VERSION ""

NS_ :

BS_:

BU_:

BO_ 3221225472 VECTOR__INDEPENDENT_SIG_MSG: 0 Vector__XXX
 SG_ CID_Pos_Long_Dec : 44|20@1+ (1,0) [0|1000000] "" Vector__XXX
 SG_ CID_Pos_Long_Int : 40|4@1+ (1,120) [120|135] "" Vector__XXX
 SG_ CID_Pos_Lat_Dec : 20|20@1+ (1,0) [0|1000000] "" Vector__XXX
 SG_ Wave_Choose_ID_Long : 0|6@1+ (1,0) [0|63] "" Vector__XXX
 SG_ Wave_Mission_State_Long : 6|2@1+ (1,0) [0|3] "" Vector__XXX
 SG_ CID_Pos_Flag_SP_Long : 8|1@1+ (1,0) [0|1] "" Vector__XXX
 SG_ CID_Pos_Flag_GP_Long : 9|1@1+ (1,0) [0|1] "" Vector__XXX
 SG_ CID_Pos_Flag_IRR1_SP_Long : 10|1@1+ (1,0) [0|1] "" Vector__XXX
 SG_ CID_Pos_Flag_IRR1_GP_Long : 11|1@1+ (1,0) [0|1] "" Vector__XXX
 SG_ CID_Pos_Flag_IRR2_SP_Long : 12|1@1+ (1,0) [0|1] "" Vector__XXX
 SG_ CID_Pos_Flag_IRR2_GP_Long : 13|1@1+ (1,0) [0|1] "" Vector__XXX
 SG_ Wave_Send_Pos_complete_flag_Long : 14|1@1+ (1,0) [0|1] "" Vector__XXX
 SG_ CID_Pos_Long : 16|32@1- (1,0) [0|0] "" Vector__XXX
 SG_ Wave_Path_CID_CTC_Long : 55|1@1+ (1,0) [0|1] "" Vector__XXX
 SG_ CID_Pos_IR_Num_Long : 48|2@1+ (1,0) [0|2] "" Vector__XXX
 SG_ Wave_Choose_ID_Lat : 0|6@1+ (1,0) [0|63] "" Vector__XXX
 SG_ Wave_Mission_State_Lat : 6|2@1+ (1,0) [0|3] "" Vector__XXX
 SG_ CID_Pos_Flag_SP_Lat : 8|1@1+ (1,0) [0|1] "" Vector__XXX
 SG_ CID_Pos_Flag_GP_Lat : 9|1@1+ (1,0) [0|1] "" Vector__XXX
 SG_ CID_Pos_Flag_IRR1_SP_Lat : 10|1@1+ (1,0) [0|1] "" Vector__XXX
 SG_ CID_Pos_Flag_IRR1_GP_Lat : 11|1@1+ (1,0) [0|1] "" Vector__XXX
 SG_ CID_Pos_Flag_IRR2_SP_Lat : 12|1@1+ (1,0) [0|1] "" Vector__XXX
 SG_ CID_Pos_Flag_IRR2_GP_Lat : 13|1@1+ (1,0) [0|1] "" Vector__XXX
 SG_ Wave_Send_Pos_complete_flag_Lat : 14|1@1+ (1,0) [0|1] "" Vector__XXX
 SG_ CID_Pos_Lat : 16|32@1- (1,0) [0|0] "" Vector__XXX
 SG_ Wave_Path_CID_CTC_Lat : 55|1@1+ (1,0) [0|1] "" Vector__XXX
 SG_ CID_Pos_IR_Num_Lat : 48|2@1+ (1,0) [0|2] "" Vector__XXX
 SG_ NewSignal_0032 : 40|8@1+ (1,0) [0|0] "" Vector__XXX
 SG_ PS1_Choose_SP_Lat_CNT : 56|8@1+ (1,0) [0|255] "" Vector__XXX
 SG_ PS1_Choose_SP_Lat_CTC : 55|1@1+ (1,0) [0|1] "" Vector__XXX
 SG_ PS1_Mission_State_MSP_Lat : 40|2@1+ (1,0) [0|3] "" Vector__XXX
 SG_ PS1_Choose_IRR_Num_MSP_Lat : 38|2@1+ (1,0) [0|2] "" Vector__XXX
 SG_ PS1_Choose_ID_MSP_Lat : 32|6@1+ (1,0) [0|63] "" Vector__XXX
 SG_ PS1_Mission_Choose_SP_Lat : 0|32@1- (1,0) [0|0] "" Vector__XXX
 SG_ PS1_Choose_SP_Long_CNT : 56|8@1+ (1,0) [0|255] "" Vector__XXX
 SG_ PS1_Choose_SP_Long_CTC : 55|1@1+ (1,0) [0|1] "" Vector__XXX
 SG_ PS1_Mission_State_MSP_Long : 40|2@1+ (1,0) [0|3] "" Vector__XXX
 SG_ PS1_Choose_IRR_Num_MSP_Long : 38|2@1+ (1,0) [0|2] "" Vector__XXX
 SG_ PS1_Choose_ID_MSP_Long : 32|6@1+ (1,0) [0|63] "" Vector__XXX
 SG_ PS1_Mission_Choose_SP_Long : 0|32@1- (1,0) [0|0] "" Vector__XXX
 SG_ PS1_Choose_GP_Lat_CNT : 56|8@1+ (1,0) [0|255] "" Vector__XXX
 SG_ PS1_Choose_GP_Lat_CTC : 55|1@1+ (1,0) [0|1] "" Vector__XXX
 SG_ PS1_Mission_State_MGP_Lat : 40|2@1+ (1,0) [0|3] "" Vector__XXX
 SG_ PS1_Choose_IRR_Num_MGP_Lat : 38|2@1+ (1,0) [0|2] "" Vector__XXX
 SG_ PS1_Choose_ID_MGP_Lat : 32|6@1+ (1,0) [0|63] "" Vector__XXX
 SG_ Wave_Path_Next_Dec_Lat : 0|12@1- (1,0) [0|0] "" Vector__XXX
 SG_ Wave_Path_Next_Dec_Long : 0|12@1- (1,0) [0|0] "" Vector__XXX
 SG_ Wave_Path_Prev_Dec_Lat : 0|12@1- (1,0) [0|0] "" Vector__XXX
 SG_ Wave_Path_Prev_Dec_Long : 0|12@1- (1,0) [0|0] "" Vector__XXX
 SG_ Wave_Path_Next_2_Dec_Lat : 0|12@1- (1,0) [0|0] "" Vector__XXX
 SG_ Wave_Path_Next_2_Dec_Long : 0|12@1- (1,0) [0|0] "" Vector__XXX
 SG_ PS1_Mission_Choose_GP_Long : 0|32@1- (1,0) [0|0] "" Vector__XXX
 SG_ PS1_Choose_ID_MGP_Long : 32|6@1+ (1,0) [0|63] "" Vector__XXX
 SG_ PS1_Choose_IRR_Num_MGP_Long : 38|2@1+ (1,0) [0|2] "" Vector__XXX
 SG_ PS1_Mission_State_MGP_Long : 40|2@1+ (1,0) [0|3] "" Vector__XXX
 SG_ PS1_Choose_GP_Long_CTC : 55|1@1+ (1,0) [0|1] "" Vector__XXX
 SG_ PS1_Choose_GP_Long_CNT : 56|8@1+ (1,0) [0|255] "" Vector__XXX
 SG_ PS1_Mission_Choose_IR1_SP_Lat : 0|32@1- (1,0) [0|0] "" Vector__XXX
 SG_ PS1_Choose_ID_IR1SP_Lat : 32|6@1+ (1,0) [0|63] "" Vector__XXX
 SG_ PS1_Choose_IRR_Num_IR1SP_Lat : 38|2@1+ (1,0) [0|2] "" Vector__XXX
 SG_ PS1_Mission_State_IR1SP_Lat : 40|2@1+ (1,0) [0|3] "" Vector__XXX
 SG_ PS1_Choose_IR1_SP_Lat_CTC : 55|1@1+ (1,0) [0|1] "" Vector__XXX
 SG_ PS1_Choose_IR1_SP_Lat_CNT : 56|8@1+ (1,0) [0|255] "" Vector__XXX
 SG_ PS1_Mission_Choose_IR1_SP_Long : 0|32@1- (1,0) [0|0] "" Vector__XXX
 SG_ PS1_Choose_ID_IR1SP_Long : 32|6@1+ (1,0) [0|63] "" Vector__XXX
 SG_ PS1_Choose_IRR_Num_IR1SP_Long : 38|2@1+ (1,0) [0|2] "" Vector__XXX
 SG_ PS1_Mission_State_IR1SP_Long : 40|2@1+ (1,0) [0|3] "" Vector__XXX
 SG_ PS1_Choose_IR1_SP_Long_CTC : 55|1@1+ (1,0) [0|1] "" Vector__XXX
 SG_ PS1_Choose_IR1_SP_Long_CNT : 56|8@1+ (1,0) [0|255] "" Vector__XXX
 SG_ PS1_Choose_ID_IR1GP_Lat : 32|6@1+ (1,0) [0|63] "" Vector__XXX
 SG_ PS1_Choose_IR1_GP_Lat_CNT : 56|8@1+ (1,0) [0|255] "" Vector__XXX
 SG_ PS1_Choose_IR1_GP_Lat_CTC : 55|1@1+ (1,0) [0|1] "" Vector__XXX
 SG_ PS1_Mission_State_IR1GP_Lat : 40|2@1+ (1,0) [0|3] "" Vector__XXX
 SG_ Wave_Course_State : 60|2@1+ (1,0) [0|0] "" Vector__XXX
 SG_ Path_IC_ID_Prev : 0|6@1+ (1,0) [0|63] "" Vector__XXX
 SG_ Prve_Start_Lane_ID : 8|4@1+ (1,0) [0|7] "" Vector__XXX
 SG_ Prev_End_Lane_ID : 12|4@1+ (1,0) [0|7] "" Vector__XXX
 SG_ Path_IC_ID_Next : 16|6@1+ (1,0) [0|63] "" Vector__XXX
 SG_ Next_Start_Lane_ID : 24|4@1+ (1,0) [0|7] "" Vector__XXX
 SG_ Next_End_Lane_ID : 28|4@1+ (1,0) [0|7] "" Vector__XXX
 SG_ Path_IC_ID_NNext : 32|6@1+ (1,0) [0|63] "" Vector__XXX
 SG_ NNext_Start_Lane_ID : 40|4@1+ (1,0) [0|7] "" Vector__XXX
 SG_ NNext_End_Lane_ID : 44|4@1+ (1,0) [0|7] "" Vector__XXX
 SG_ Prev_SP_Flag : 6|1@1+ (1,0) [0|0] "" Vector__XXX
 SG_ Prev_GP_Flag : 7|1@1+ (1,0) [0|0] "" Vector__XXX
 SG_ Prev_IRR1_SP_Flag : 51|1@1+ (1,0) [0|0] "" Vector__XXX
 SG_ Prev_IRR1_GP_Flag : 50|1@1+ (1,0) [0|0] "" Vector__XXX
 SG_ Prev_IRR2_SP_Flag : 49|1@1+ (1,0) [0|0] "" Vector__XXX
 SG_ Prev_IRR2_GP_Flag : 48|1@1+ (1,0) [0|0] "" Vector__XXX
 SG_ Next_SP_Flag : 22|1@1+ (1,0) [0|0] "" Vector__XXX
 SG_ Next_GP_Flag : 23|1@1+ (1,0) [0|0] "" Vector__XXX
 SG_ Next_IRR1_SP_Flag : 55|1@1+ (1,0) [0|0] "" Vector__XXX
 SG_ Next_IRR1_GP_Flag : 54|1@1+ (1,0) [0|0] "" Vector__XXX
 SG_ Next_IRR2_SP_Flag : 53|1@1+ (1,0) [0|0] "" Vector__XXX
 SG_ Next_IRR2_GP_Flag : 52|1@1+ (1,0) [0|0] "" Vector__XXX
 SG_ NNext_SP_Flag : 38|1@1+ (1,0) [0|0] "" Vector__XXX
 SG_ NNext_GP_Flag : 39|1@1+ (1,0) [0|0] "" Vector__XXX
 SG_ NNext_IRR1_SP_Flag : 59|1@1+ (1,0) [0|0] "" Vector__XXX
 SG_ NNext_IRR1_GP_Flag : 58|1@1+ (1,0) [0|0] "" Vector__XXX
 SG_ NNext_IRR2_SP_Flag : 57|1@1+ (1,0) [0|0] "" Vector__XXX
 SG_ NNext_IRR2_GP_Flag : 56|1@1+ (1,0) [0|0] "" Vector__XXX
 SG_ Wave_Path_CMD_Info_CTC : 63|1@1+ (1,0) [0|0] "" Vector__XXX
 SG_ Wave_Path_IR2_Pos_GP_Long_Dec : 0|32@1+ (1,0) [0|100000000] "" Vector__XXX
 SG_ Wave_Path_IR2_Pos_GP_Long_Int : 32|8@1+ (1,0) [0|255] "" Vector__XXX
 SG_ Wave_Path_IR2_GP_Lane_Long : 40|4@1+ (1,0) [0|7] "" Vector__XXX
 SG_ Path_CMD_IR2_GP_Long_CTC : 55|1@1+ (1,0) [0|1] "" Vector__XXX
 SG_ Path_CMD_IR2_GP_Long_CNT : 56|8@1+ (1,0) [0|255] "" Vector__XXX
 SG_ Wave_Path_IR2_Pos_GP_Lat_Dec : 0|32@1+ (1,0) [0|100000000] "" Vector__XXX
 SG_ Wave_Path_IR2_Pos_GP_Lat_Int : 32|8@1+ (1,0) [0|255] "" Vector__XXX
 SG_ Wave_Path_IR2_GP_Lane_Lat : 40|4@1+ (1,0) [0|7] "" Vector__XXX
 SG_ Path_CMD_IR2_GP_Lat_CTC : 55|1@1+ (1,0) [0|1] "" Vector__XXX
 SG_ Path_CMD_IR2_GP_Lat_CNT : 56|8@1+ (1,0) [0|255] "" Vector__XXX
 SG_ Wave_Path_IR2_Pos_SP_Long_Dec : 0|32@1+ (1,0) [0|100000000] "" Vector__XXX
 SG_ Wave_Path_IR2_Pos_SP_Long_Int : 32|8@1+ (1,0) [0|255] "" Vector__XXX
 SG_ Wave_Path_IR2_SP_Lane_Long : 40|4@1+ (1,0) [0|7] "" Vector__XXX
 SG_ Path_CMD_IR2_SP_Long_CTC : 55|1@1+ (1,0) [0|1] "" Vector__XXX
 SG_ Path_CMD_IR2_SP_Long_CNT : 56|8@1+ (1,0) [0|255] "" Vector__XXX
 SG_ Wave_Path_IR2_Pos_SP_Lat_Dec : 0|32@1+ (1,0) [0|100000000] "" Vector__XXX
 SG_ Wave_Path_IR2_Pos_SP_Lat_Int : 32|8@1+ (1,0) [0|255] "" Vector__XXX
 SG_ Wave_Path_IR2_SP_Lane_Lat : 40|4@1+ (1,0) [0|7] "" Vector__XXX
 SG_ Path_CMD_IR2_SP_Lat_CTC : 55|1@1+ (1,0) [0|1] "" Vector__XXX
 SG_ Path_CMD_IR2_SP_Lat_CNT : 56|8@1+ (1,0) [0|255] "" Vector__XXX
 SG_ Wave_Path_IR1_Pos_GP_Long_Dec : 0|32@1+ (1,0) [0|100000000] "" Vector__XXX
 SG_ Wave_Path_IR1_Pos_GP_Long_Int : 32|8@1+ (1,0) [0|255] "" Vector__XXX
 SG_ Wave_Path_IR1_GP_Lane_Long : 40|4@1+ (1,0) [0|7] "" Vector__XXX
 SG_ Path_CMD_IR1_GP_Long_CTC : 55|1@1+ (1,0) [0|1] "" Vector__XXX
 SG_ Path_CMD_IR1_GP_Long_CNT : 56|8@1+ (1,0) [0|255] "" Vector__XXX
 SG_ Wave_Path_IR1_Pos_GP_Lat_Dec : 0|32@1+ (1,0) [0|100000000] "" Vector__XXX
 SG_ Wave_Path_IR1_Pos_GP_Lat_Int : 32|8@1+ (1,0) [0|255] "" Vector__XXX
 SG_ Wave_Path_IR1_GP_Lane_Lat : 40|4@1+ (1,0) [0|7] "" Vector__XXX
 SG_ Path_CMD_IR1_GP_Lat_CTC : 55|1@1+ (1,0) [0|1] "" Vector__XXX
 SG_ Path_CMD_IR1_GP_Lat_CNT : 56|8@1+ (1,0) [0|255] "" Vector__XXX
 SG_ Wave_Path_IR1_Pos_SP_Long_Dec : 0|32@1+ (1,0) [0|100000000] "" Vector__XXX
 SG_ Wave_Path_IR1_Pos_SP_Long_Int : 32|8@1+ (1,0) [0|255] "" Vector__XXX
 SG_ Wave_Path_IR1_SP_Lane_Long : 40|4@1+ (1,0) [0|7] "" Vector__XXX
 SG_ Path_CMD_IR1_SP_Long_CTC : 55|1@1+ (1,0) [0|1] "" Vector__XXX
 SG_ Path_CMD_IR1_SP_Long_CNT : 56|8@1+ (1,0) [0|255] "" Vector__XXX
 SG_ Wave_Path_IR1_Pos_SP_Lat_Dec : 0|32@1+ (1,0) [0|100000000] "" Vector__XXX
 SG_ Wave_Path_IR1_Pos_SP_Lat_Int : 32|8@1+ (1,0) [0|255] "" Vector__XXX
 SG_ Wave_Path_IR1_SP_Lane_Lat : 40|4@1+ (1,0) [0|7] "" Vector__XXX
 SG_ Path_CMD_IR1_SP_Lat_CTC : 55|1@1+ (1,0) [0|1] "" Vector__XXX
 SG_ Path_CMD_IR1_SP_Lat_CNT : 56|8@1+ (1,0) [0|255] "" Vector__XXX
 SG_ Wave_Path_M_Pos_GP_Long_Dec : 0|32@1+ (1,0) [0|100000000] "" Vector__XXX
 SG_ Wave_Path_M_Pos_GP_Long_Int : 32|8@1+ (1,0) [0|255] "" Vector__XXX
 SG_ Wave_Path_M_GP_Lane_Long : 40|4@1+ (1,0) [0|7] "" Vector__XXX
 SG_ Path_CMD_M_GP_Long_CTC : 55|1@1+ (1,0) [0|1] "" Vector__XXX
 SG_ Path_CMD_M_GP_Long_CNT : 56|8@1+ (1,0) [0|255] "" Vector__XXX
 SG_ Wave_Path_M_Pos_GP_Lat_Dec : 0|32@1+ (1,0) [0|100000000] "" Vector__XXX
 SG_ Wave_Path_M_Pos_GP_Lat_Int : 32|8@1+ (1,0) [0|255] "" Vector__XXX
 SG_ Wave_Path_M_GP_Lane_Lat : 40|4@1+ (1,0) [0|7] "" Vector__XXX
 SG_ Path_CMD_M_GP_Lat_CTC : 55|1@1+ (1,0) [0|1] "" Vector__XXX
 SG_ Path_CMD_M_GP_Lat_CNT : 56|8@1+ (1,0) [0|255] "" Vector__XXX
 SG_ Wave_Path_M_Pos_SP_Long_Dec : 0|32@1+ (1,0) [0|100000000] "" Vector__XXX
 SG_ Wave_Path_M_Pos_SP_Long_Int : 32|8@1+ (1,0) [0|255] "" Vector__XXX
 SG_ Wave_Path_M_SP_Lane_Long : 40|4@1+ (1,0) [0|7] "" Vector__XXX
 SG_ Path_CMD_M_SP_Long_CTC : 55|1@1+ (1,0) [0|1] "" Vector__XXX
 SG_ Path_CMD_M_SP_Long_CNT : 56|8@1+ (1,0) [0|255] "" Vector__XXX
 SG_ Wave_Path_M_Pos_SP_Lat_Dec : 0|32@1+ (1,0) [0|100000000] "" Vector__XXX
 SG_ Wave_Path_M_Pos_SP_Lat_Int : 32|8@1+ (1,0) [0|255] "" Vector__XXX
 SG_ Wave_Path_M_SP_Lane_Lat : 40|4@1+ (1,0) [0|7] "" Vector__XXX
 SG_ Path_CMD_M_SP_Lat_CTC : 55|1@1+ (1,0) [0|1] "" Vector__XXX
 SG_ Path_CMD_M_SP_Lat_CNT : 56|8@1+ (1,0) [0|255] "" Vector__XXX
 SG_ PS1_Mission_Choose_IR2_GP_Long : 0|32@1- (1,0) [0|0] "" Vector__XXX
 SG_ PS1_Choose_ID_IR2GP_Long : 32|6@1+ (1,0) [0|63] "" Vector__XXX
 SG_ PS1_Choose_IRR_Num_IR2GP_Long : 38|2@1+ (1,0) [0|2] "" Vector__XXX
 SG_ PS1_Mission_State_IR2GP_Long : 40|2@1+ (1,0) [0|3] "" Vector__XXX
 SG_ PS1_Choose_IR2_GP_Long_CTC : 55|1@1+ (1,0) [0|1] "" Vector__XXX
 SG_ PS1_Choose_IR2_GP_Long_CNT : 56|8@1+ (1,0) [0|255] "" Vector__XXX
 SG_ PS1_Mission_Choose_IR2_GP_Lat : 0|32@1- (1,0) [0|0] "" Vector__XXX
 SG_ PS1_Choose_ID_IR2GP_Lat : 32|6@1+ (1,0) [0|63] "" Vector__XXX
 SG_ PS1_Choose_IRR_Num_IR2GP_Lat : 38|2@1+ (1,0) [0|2] "" Vector__XXX
 SG_ PS1_Mission_State_IR2GP_Lat : 40|2@1+ (1,0) [0|3] "" Vector__XXX
 SG_ PS1_Choose_IR2_GP_Lat_CTC : 55|1@1+ (1,0) [0|1] "" Vector__XXX
 SG_ PS1_Choose_IR2_GP_Lat_CNT : 56|8@1+ (1,0) [0|255] "" Vector__XXX
 SG_ PS1_Mission_Choose_IR2_SP_Long : 0|32@1- (1,0) [0|0] "" Vector__XXX
 SG_ PS1_Choose_ID_IR2SP_Long : 32|6@1+ (1,0) [0|63] "" Vector__XXX
 SG_ PS1_Choose_IRR_Num_IR2SP_Long : 38|2@1+ (1,0) [0|2] "" Vector__XXX
 SG_ PS1_Mission_State_IR2SP_Long : 40|2@1+ (1,0) [0|3] "" Vector__XXX
 SG_ PS1_Choose_IR2_SP_Long_CTC : 55|1@1+ (1,0) [0|1] "" Vector__XXX
 SG_ PS1_Choose_IR2_SP_Long_CNT : 56|8@1+ (1,0) [0|255] "" Vector__XXX
 SG_ PS1_Mission_Choose_IR2_SP_Lat : 0|32@1- (1,0) [0|0] "" Vector__XXX
 SG_ PS1_Choose_ID_IR2SP_Lat : 32|6@1+ (1,0) [0|63] "" Vector__XXX
 SG_ PS1_Choose_IRR_Num_IR2SP_Lat : 38|2@1+ (1,0) [0|2] "" Vector__XXX
 SG_ PS1_Mission_State_IR2SP_Lat : 40|2@1+ (1,0) [0|3] "" Vector__XXX
 SG_ PS1_Choose_IR2_SP_Lat_CTC : 55|1@1+ (1,0) [0|1] "" Vector__XXX
 SG_ PS1_Choose_IR2_SP_Lat_CNT : 56|8@1+ (1,0) [0|255] "" Vector__XXX
 SG_ PS1_Mission_Choose_IR1_GP_Long : 0|32@1- (1,0) [0|0] "" Vector__XXX
 SG_ PS1_Choose_ID_IR1GP_Long : 32|6@1+ (1,0) [0|63] "" Vector__XXX
 SG_ PS1_Choose_IRR_Num_IR1GP_Long : 38|2@1+ (1,0) [0|2] "" Vector__XXX
 SG_ PS1_Mission_State_IR1GP_Long : 40|2@1+ (1,0) [0|3] "" Vector__XXX
 SG_ PS1_Choose_IR1_GP_Long_CTC : 55|1@1+ (1,0) [0|1] "" Vector__XXX
 SG_ PS1_Choose_IR1_GP_Long_CNT : 56|8@1+ (1,0) [0|255] "" Vector__XXX

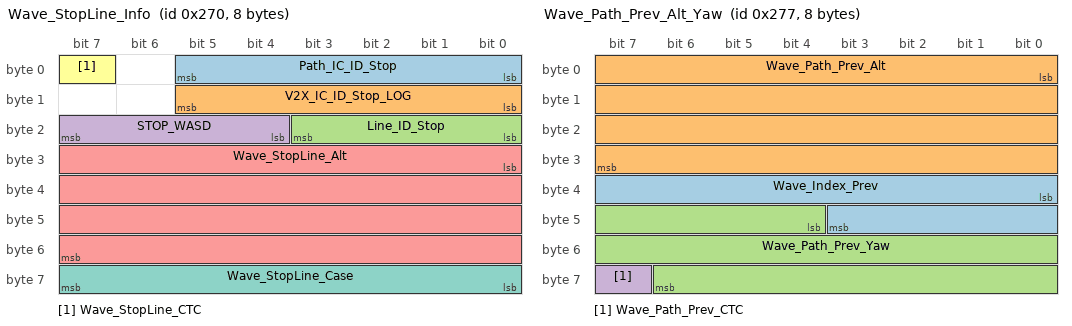
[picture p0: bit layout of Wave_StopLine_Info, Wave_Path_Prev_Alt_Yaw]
BO_ 624 Wave_StopLine_Info: 8 Vector__XXX
 SG_ Path_IC_ID_Stop : 0|6@1+ (1,0) [0|63] "" Vector__XXX
 SG_ V2X_IC_ID_Stop_LOG : 8|6@1+ (1,0) [0|63] "" Vector__XXX
 SG_ Line_ID_Stop : 16|4@1+ (1,0) [0|7] "" Vector__XXX
 SG_ STOP_WASD : 20|4@1+ (1,0) [0|12] "" Vector__XXX
 SG_ Wave_StopLine_Alt : 24|32@1- (1,0) [0|0] "" Vector__XXX
 SG_ Wave_StopLine_CTC : 7|1@1+ (1,0) [0|0] "" Vector__XXX
 SG_ Wave_StopLine_Case : 56|8@1+ (1,0) [0|0] "" Vector__XXX

BO_ 625 Wave_StopLine_Lat: 8 Vector__XXX
 SG_ Wave_StopLine_Lat : 0|64@1- (1,0) [0|0] "" Vector__XXX

BO_ 626 Wave_StopLine_Long: 8 Vector__XXX
 SG_ Wave_StopLine_Long : 0|64@1- (1,0) [0|0] "" Vector__XXX

BO_ 629 Wave_Path_Prev_Lat_Dec_2: 8 Vector__XXX
 SG_ Wave_Path_Prev_Lat_Dec_2 : 0|64@1- (1,0) [0|0] "" Vector__XXX

BO_ 630 Wave_Path_Prev_Long_Dec_2: 8 Vector__XXX
 SG_ Wave_Path_Prev_Long_Dec_2 : 0|64@1- (1,0) [0|100000000] "" Vector__XXX

BO_ 631 Wave_Path_Prev_Alt_Yaw: 8 Vector__XXX
 SG_ Wave_Index_Prev : 32|12@1+ (1,0) [0|16383] "" Vector__XXX
 SG_ Wave_Path_Prev_Alt : 0|32@1- (1,0) [0|0] "" Vector__XXX
 SG_ Wave_Path_Prev_Yaw : 44|19@1- (0.001,0) [-180|180] "" Vector__XXX
 SG_ Wave_Path_Prev_CTC : 63|1@1+ (1,0) [0|1] "" Vector__XXX

BO_ 632 Wave_Path_Next_Lat_Dec_2: 8 Vector__XXX
 SG_ Wave_Path_Next_Lat_Dec_2 : 0|64@1- (1,0) [0|0] "" Vector__XXX

BO_ 633 Wave_Path_Next_Long_Dec_2: 8 Vector__XXX
 SG_ Wave_Path_Next_Long_Dec_2 : 0|64@1- (1,0) [0|0] "" Vector__XXX

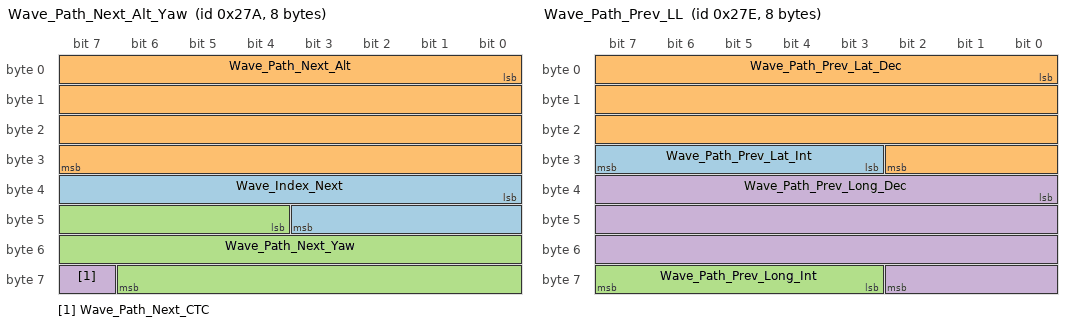
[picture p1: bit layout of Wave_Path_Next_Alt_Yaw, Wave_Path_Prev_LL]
BO_ 634 Wave_Path_Next_Alt_Yaw: 8 Vector__XXX
 SG_ Wave_Index_Next : 32|12@1+ (1,0) [0|16383] "" Vector__XXX
 SG_ Wave_Path_Next_Alt : 0|32@1- (1,0) [0|0] "" Vector__XXX
 SG_ Wave_Path_Next_Yaw : 44|19@1- (0.001,0) [-180|180] "" Vector__XXX
 SG_ Wave_Path_Next_CTC : 63|1@1+ (1,0) [0|1] "" Vector__XXX

BO_ 638 Wave_Path_Prev_LL: 8 Vector__XXX
 SG_ Wave_Path_Prev_Lat_Int : 27|5@1+ (1,20) [20|51] "" Vector__XXX
 SG_ Wave_Path_Prev_Lat_Dec : 0|27@1- (1,0) [0|100000000] "" Vector__XXX
 SG_ Wave_Path_Prev_Long_Int : 59|5@1+ (1,111) [111|142] "" Vector__XXX
 SG_ Wave_Path_Prev_Long_Dec : 32|27@1- (1,0) [0|100000000] "" Vector__XXX

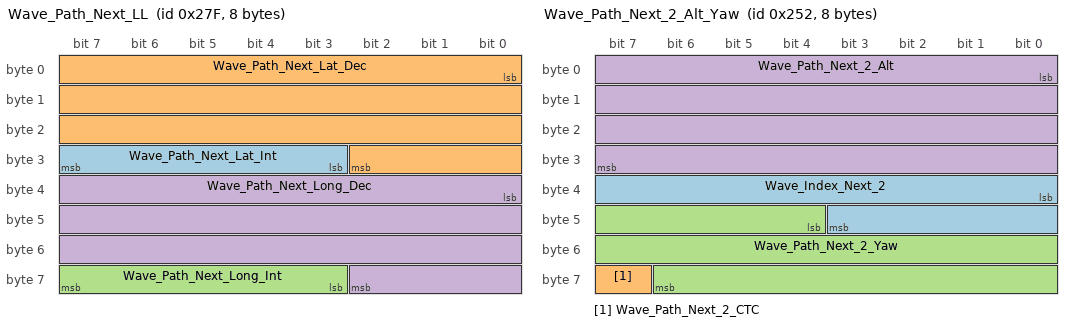
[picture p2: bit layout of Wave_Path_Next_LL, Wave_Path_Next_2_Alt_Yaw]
BO_ 639 Wave_Path_Next_LL: 8 Vector__XXX
 SG_ Wave_Path_Next_Lat_Int : 27|5@1+ (1,20) [20|51] "" Vector__XXX
 SG_ Wave_Path_Next_Lat_Dec : 0|27@1- (1,0) [0|100000000] "" Vector__XXX
 SG_ Wave_Path_Next_Long_Int : 59|5@1+ (1,111) [111|142] "" Vector__XXX
 SG_ Wave_Path_Next_Long_Dec : 32|27@1- (1,0) [0|100000000] "" Vector__XXX

BO_ 592 Wave_Path_Next_2_Lat_Dec_2: 8 Vector__XXX
 SG_ Wave_Path_Next_2_Lat_Dec_2 : 0|64@1- (1,0) [0|0] "" Vector__XXX

BO_ 593 Wave_Path_Next_2_Long_Dec_2: 8 Vector__XXX
 SG_ Wave_Path_Next_2_Long_Dec_2 : 0|64@1- (1,0) [0|0] "" Vector__XXX

BO_ 594 Wave_Path_Next_2_Alt_Yaw: 8 Vector__XXX
 SG_ Wave_Index_Next_2 : 32|12@1+ (1,0) [0|16383] "" Vector__XXX
 SG_ Wave_Path_Next_2_CTC : 63|1@1+ (1,0) [0|0] "" Vector__XXX
 SG_ Wave_Path_Next_2_Yaw : 44|19@1- (0.001,0) [-180|180] "" Vector__XXX
 SG_ Wave_Path_Next_2_Alt : 0|32@1- (1,0) [0|0] "" Vector__XXX

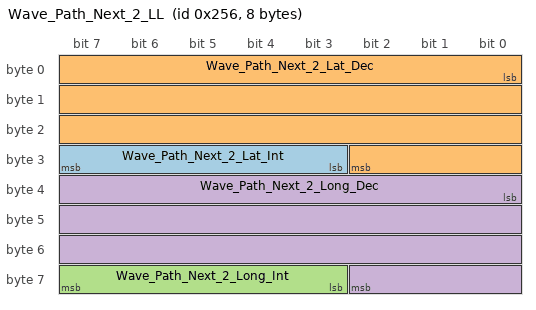
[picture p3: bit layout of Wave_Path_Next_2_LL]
BO_ 598 Wave_Path_Next_2_LL: 8 Vector__XXX
 SG_ Wave_Path_Next_2_Lat_Int : 27|5@1+ (1,20) [20|51] "" Vector__XXX
 SG_ Wave_Path_Next_2_Lat_Dec : 0|27@1- (1,0) [0|100000000] "" Vector__XXX
 SG_ Wave_Path_Next_2_Long_Int : 59|5@1+ (1,111) [111|142] "" Vector__XXX
 SG_ Wave_Path_Next_2_Long_Dec : 32|27@1- (1,0) [0|100000000] "" Vector__XXX

BO_ 1 Wave_Path_Prev_Lat_Dec_1: 8 Vector__XXX
 SG_ Wave_Path_Prev_Lat_Dec_1 : 0|64@1- (1,0) [0|0] "" Vector__XXX

BO_ 2 Wave_Path_Prev_Long_Dec_1: 8 Vector__XXX
 SG_ Wave_Path_Prev_Long_Dec_1 : 0|64@1- (1,0) [0|0] "" Vector__XXX

BO_ 3 Wave_Path_Next_Lat_Dec_1: 8 Vector__XXX
 SG_ Wave_Path_Next_Lat_Dec_1 : 0|64@1- (1,0) [0|0] "" Vector__XXX

BO_ 4 Wave_Path_Next_Long_Dec_1: 8 Vector__XXX
 SG_ Wave_Path_Next_Long_Dec_1 : 0|64@1- (1,0) [0|0] "" Vector__XXX

BO_ 5 Wave_Path_Next_2_Lat_Dec_1: 8 Vector__XXX
 SG_ Wave_Path_Next_2_Lat_Dec_1 : 0|64@1- (1,0) [0|0] "" Vector__XXX

BO_ 6 Wave_Path_Next_2_Long_Dec_1: 8 Vector__XXX
 SG_ Wave_Path_Next_2_Long_Dec_1 : 0|64@1- (1,0) [0|0] "" Vector__XXX

BO_ 7 Wave_Path_info: 8 Vector__XXX
 SG_ CNT : 56|8@1+ (1,0) [0|255] "" Vector__XXX
 SG_ CTC : 7|1@1+ (1,0) [0|0] "" Vector__XXX

CM_ SG_ 3221225472 Wave_Mission_State_Long "0:선택안함 1:선택중 2:수행중 3:완료";
CM_ SG_ 3221225472 Wave_Send_Pos_complete_flag_Long "좌표정보를 다 Send했을 때 1로 올린다";
CM_ SG_ 3221225472 Wave_Mission_State_Lat "0:선택안함 1:선택중 2:수행중 3:완료";
CM_ SG_ 3221225472 Wave_Send_Pos_complete_flag_Lat "좌표정보를 다 Send했을 때 1로 올린다";
CM_ SG_ 3221225472 PS1_Mission_State_MSP_Lat "현재 PS1의 구동상태
0:대기중
1:V2X정보 수신중
2:미션 선택 중
3:미션 선택 완료 -> 미션 수행";
CM_ SG_ 3221225472 PS1_Choose_IRR_Num_MSP_Lat "선택한 미션이 갖는 비정형 개수";
CM_ SG_ 3221225472 PS1_Choose_ID_MSP_Lat "미션1에서 선택한 미션ID";
CM_ SG_ 3221225472 PS1_Mission_State_MSP_Long "현재 PS1의 구동상태
0:대기중
1:V2X정보 수신중
2:미션 선택 중
3:미션 선택 완료 -> 미션 수행";
CM_ SG_ 3221225472 PS1_Choose_IRR_Num_MSP_Long "선택한 미션이 갖는 비정형 개수";
CM_ SG_ 3221225472 PS1_Choose_ID_MSP_Long "미션1에서 선택한 미션ID";
CM_ SG_ 3221225472 PS1_Mission_State_MGP_Lat "현재 PS1의 구동상태
0:대기중
1:V2X정보 수신중
2:미션 선택 중
3:미션 선택 완료 -> 미션 수행";
CM_ SG_ 3221225472 PS1_Choose_IRR_Num_MGP_Lat "선택한 미션이 갖는 비정형 개수";
CM_ SG_ 3221225472 PS1_Choose_ID_MGP_Lat "미션1에서 선택한 미션ID";
CM_ SG_ 3221225472 PS1_Choose_ID_MGP_Long "미션1에서 선택한 미션ID";
CM_ SG_ 3221225472 PS1_Choose_IRR_Num_MGP_Long "선택한 미션이 갖는 비정형 개수";
CM_ SG_ 3221225472 PS1_Mission_State_MGP_Long "현재 PS1의 구동상태
0:대기중
1:V2X정보 수신중
2:미션 선택 중
3:미션 선택 완료 -> 미션 수행";
CM_ SG_ 3221225472 PS1_Choose_ID_IR1SP_Lat "미션1에서 선택한 미션ID";
CM_ SG_ 3221225472 PS1_Choose_IRR_Num_IR1SP_Lat "선택한 미션이 갖는 비정형 개수";
CM_ SG_ 3221225472 PS1_Mission_State_IR1SP_Lat "현재 PS1의 구동상태
0:대기중
1:V2X정보 수신중
2:미션 선택 중
3:미션 선택 완료 -> 미션 수행";
CM_ SG_ 3221225472 PS1_Choose_ID_IR1SP_Long "미션1에서 선택한 미션ID";
CM_ SG_ 3221225472 PS1_Choose_IRR_Num_IR1SP_Long "선택한 미션이 갖는 비정형 개수";
CM_ SG_ 3221225472 PS1_Mission_State_IR1SP_Long "현재 PS1의 구동상태
0:대기중
1:V2X정보 수신중
2:미션 선택 중
3:미션 선택 완료 -> 미션 수행";
CM_ SG_ 3221225472 PS1_Choose_ID_IR1GP_Lat "미션1에서 선택한 미션ID";
CM_ SG_ 3221225472 PS1_Mission_State_IR1GP_Lat "현재 PS1의 구동상태
0:대기중
1:V2X정보 수신중
2:미션 선택 중
3:미션 선택 완료 -> 미션 수행";
CM_ SG_ 3221225472 Wave_Course_State "1:직진
2:좌회전
3:우회전
0:신호무시";
CM_ SG_ 3221225472 Path_IC_ID_Prev "영훈이가 임의로 교차로 중심점을 기준으로 생성한 노드
10번대, 20번대 -> V2X정보를 기준으로 만든 노드 인덱싱
30번대 -> V2X 정보가 없을때 사용하는 노드 인덱싱";
CM_ SG_ 3221225472 Path_IC_ID_Next "영훈이가 임의로 교차로 중심점을 기준으로 생성한 노드
10번대, 20번대 -> V2X정보를 기준으로 만든 노드 인덱싱
30번대 -> V2X 정보가 없을때 사용하는 노드 인덱싱";
CM_ SG_ 3221225472 Path_IC_ID_NNext "영훈이가 임의로 교차로 중심점을 기준으로 생성한 노드
10번대, 20번대 -> V2X정보를 기준으로 만든 노드 인덱싱
30번대 -> V2X 정보가 없을때 사용하는 노드 인덱싱";
CM_ SG_ 3221225472 PS1_Choose_ID_IR2GP_Long "미션1에서 선택한 미션ID";
CM_ SG_ 3221225472 PS1_Choose_IRR_Num_IR2GP_Long "선택한 미션이 갖는 비정형 개수";
CM_ SG_ 3221225472 PS1_Mission_State_IR2GP_Long "현재 PS1의 구동상태
0:대기중
1:V2X정보 수신중
2:미션 선택 중
3:미션 선택 완료 -> 미션 수행";
CM_ SG_ 3221225472 PS1_Choose_ID_IR2GP_Lat "미션1에서 선택한 미션ID";
CM_ SG_ 3221225472 PS1_Choose_IRR_Num_IR2GP_Lat "선택한 미션이 갖는 비정형 개수";
CM_ SG_ 3221225472 PS1_Mission_State_IR2GP_Lat "현재 PS1의 구동상태
0:대기중
1:V2X정보 수신중
2:미션 선택 중
3:미션 선택 완료 -> 미션 수행";
CM_ SG_ 3221225472 PS1_Choose_ID_IR2SP_Long "미션1에서 선택한 미션ID";
CM_ SG_ 3221225472 PS1_Choose_IRR_Num_IR2SP_Long "선택한 미션이 갖는 비정형 개수";
CM_ SG_ 3221225472 PS1_Mission_State_IR2SP_Long "현재 PS1의 구동상태
0:대기중
1:V2X정보 수신중
2:미션 선택 중
3:미션 선택 완료 -> 미션 수행";
CM_ SG_ 3221225472 PS1_Choose_ID_IR2SP_Lat "미션1에서 선택한 미션ID";
CM_ SG_ 3221225472 PS1_Choose_IRR_Num_IR2SP_Lat "선택한 미션이 갖는 비정형 개수";
CM_ SG_ 3221225472 PS1_Mission_State_IR2SP_Lat "현재 PS1의 구동상태
0:대기중
1:V2X정보 수신중
2:미션 선택 중
3:미션 선택 완료 -> 미션 수행";
CM_ SG_ 3221225472 PS1_Choose_ID_IR1GP_Long "미션1에서 선택한 미션ID";
CM_ SG_ 3221225472 PS1_Choose_IRR_Num_IR1GP_Long "선택한 미션이 갖는 비정형 개수";
CM_ SG_ 3221225472 PS1_Mission_State_IR1GP_Long "현재 PS1의 구동상태
0:대기중
1:V2X정보 수신중
2:미션 선택 중
3:미션 선택 완료 -> 미션 수행";
CM_ BO_ 624 "Step3의 정지선 출력값";
CM_ BO_ 625 "Step3의 정지선 출력값";
CM_ BO_ 626 "Step3의 정지선 출력값";
CM_ BO_ 629 "Step4의 최종 OUTPUT";
CM_ BO_ 630 "Step4의 최종 OUTPUT";
CM_ BO_ 631 "Step4의 최종 OUTPUT";
CM_ BO_ 632 "Step4의 최종 OUTPUT";
CM_ BO_ 633 "Step4의 최종 OUTPUT";
CM_ BO_ 634 "Step4의 최종 OUTPUT";
CM_ BO_ 638 "이전처럼 Lat랑 Long밀릴때 백업으로 쓰는 것";
CM_ BO_ 639 "이전처럼 Lat랑 Long밀릴때 백업으로 쓰는 것";
CM_ BO_ 592 "미션 선택을 하는 Step1의 출력값
해당 출력값은 Step2의 교차로 GPP하는데 사용한다";
CM_ BO_ 593 "미션 선택을 하는 Step1의 출력값
해당 출력값은 Step2의 교차로 GPP하는데 사용한다";
CM_ BO_ 594 "미션 선택을 하는 Step1의 출력값
해당 출력값은 Step2의 교차로 GPP하는데 사용한다";
CM_ BO_ 598 "미션 선택을 하는 Step1의 출력값
해당 출력값은 Step2의 교차로 GPP하는데 사용한다";
CM_ SG_ 598 Wave_Path_Next_2_Lat_Dec "선택한 미션이 갖는 비정형 개수";
SIG_VALTYPE_ 625 Wave_StopLine_Lat : 2;
SIG_VALTYPE_ 626 Wave_StopLine_Long : 2;
SIG_VALTYPE_ 629 Wave_Path_Prev_Lat_Dec_2 : 2;
SIG_VALTYPE_ 630 Wave_Path_Prev_Long_Dec_2 : 2;
SIG_VALTYPE_ 631 Wave_Path_Prev_Alt : 1;
SIG_VALTYPE_ 632 Wave_Path_Next_Lat_Dec_2 : 2;
SIG_VALTYPE_ 633 Wave_Path_Next_Long_Dec_2 : 2;
SIG_VALTYPE_ 634 Wave_Path_Next_Alt : 1;
SIG_VALTYPE_ 638 Wave_Path_Prev_Lat_Dec : 1;
SIG_VALTYPE_ 638 Wave_Path_Prev_Long_Dec : 1;
SIG_VALTYPE_ 639 Wave_Path_Next_Lat_Dec : 1;
SIG_VALTYPE_ 639 Wave_Path_Next_Long_Dec : 1;
SIG_VALTYPE_ 592 Wave_Path_Next_2_Lat_Dec_2 : 2;
SIG_VALTYPE_ 593 Wave_Path_Next_2_Long_Dec_2 : 2;
SIG_VALTYPE_ 594 Wave_Path_Next_2_Alt : 1;
SIG_VALTYPE_ 598 Wave_Path_Next_2_Lat_Dec : 1;
SIG_VALTYPE_ 598 Wave_Path_Next_2_Long_Dec : 1;
SIG_VALTYPE_ 1 Wave_Path_Prev_Lat_Dec_1 : 2;
SIG_VALTYPE_ 2 Wave_Path_Prev_Long_Dec_1 : 2;
SIG_VALTYPE_ 3 Wave_Path_Next_Lat_Dec_1 : 2;
SIG_VALTYPE_ 4 Wave_Path_Next_Long_Dec_1 : 2;
SIG_VALTYPE_ 5 Wave_Path_Next_2_Lat_Dec_1 : 2;
SIG_VALTYPE_ 6 Wave_Path_Next_2_Long_Dec_1 : 2;
